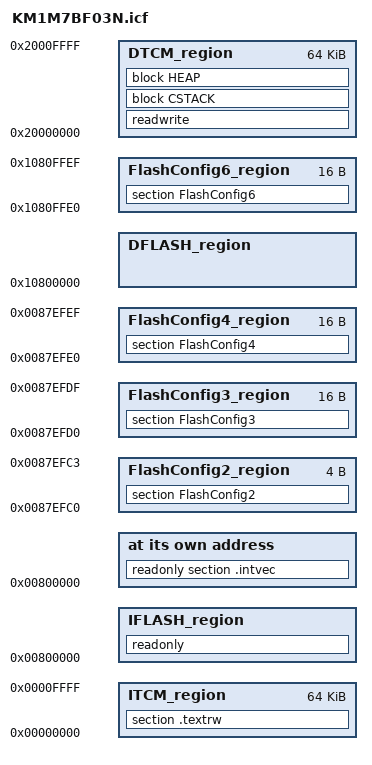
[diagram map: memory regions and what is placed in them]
/*###ICF### Section handled by ICF editor, don't touch! ****/
/*-Editor annotation file-*/
/* IcfEditorFile="$TOOLKIT_DIR$\config\ide\IcfEditor\cortex_v1_0.xml" */
/*-Specials-*/
define symbol __ICFEDIT_intvec_start__ = 0x00800000;
/*-Memory Regions-*/
define symbol __ICFEDIT_region_DTCM_start__      = 0x20000000;
define symbol __ICFEDIT_region_DTCM_end__        = 0x2000FFFF;
define symbol __ICFEDIT_region_DFLASH_start__    = 0x10800000;
define symbol __ICFEDIT_region_DFLASH_end__      = 0x1080FFFF;
define symbol __ICFEDIT_region_IFLASH_start__    = 0x00800000;
define symbol __ICFEDIT_region_IFLASH_end__      = 0x0087FFFF;
define symbol __ICFEDIT_region_ITCM_start__      = 0x00000000;
define symbol __ICFEDIT_region_ITCM_end__        = 0x0000FFFF;
/*-Sizes-*/
define symbol __ICFEDIT_size_cstack__ = 0x400;
define symbol __ICFEDIT_size_heap__   = 0x800;
/**** End of ICF editor section. ###ICF###*/

/**** Special settings for target device ****/

/*- Define symbols -*/
define symbol __FlashConfig1_start__ = 0x0087FFF8;
define symbol __FlashConfig1_end__   = 0x0087FFF8;
define symbol __FlashConfig2_start__ = 0x0087EFC0;
define symbol __FlashConfig2_end__   = 0x0087EFC3;
define symbol __FlashConfig3_start__ = 0x0087EFD0;
define symbol __FlashConfig3_end__   = 0x0087EFDF;
define symbol __FlashConfig4_start__ = 0x0087EFE0;
define symbol __FlashConfig4_end__   = 0x0087EFEF;
define symbol __FlashConfig6_start__ = 0x1080FFE0;
define symbol __FlashConfig6_end__   = 0x1080FFEF;

/* Define the memory space of 4G bytes named "mem" */
define memory mem with size = 4G;

/*- Define region in memory -*/
define region IFLASH_region    = mem:[from __ICFEDIT_region_IFLASH_start__ to __ICFEDIT_region_IFLASH_end__] - mem:[from __FlashConfig1_start__ to __FlashConfig1_end__] - mem:[from __FlashConfig2_start__ to __FlashConfig2_end__] - mem:[from __FlashConfig3_start__ to __FlashConfig3_end__] - mem:[from __FlashConfig4_start__ to __FlashConfig4_end__];
define region DFLASH_region    = mem:[from __ICFEDIT_region_DFLASH_start__ to __ICFEDIT_region_DFLASH_end__] - mem:[from __FlashConfig6_start__ to __FlashConfig6_end__];
define region ITCM_region      = mem:[from __ICFEDIT_region_ITCM_start__ to __ICFEDIT_region_ITCM_end__];
define region DTCM_region      = mem:[from __ICFEDIT_region_DTCM_start__ to __ICFEDIT_region_DTCM_end__];

define region FlashConfig1_region = mem:[from __FlashConfig1_start__ to __FlashConfig1_end__];
define region FlashConfig2_region = mem:[from __FlashConfig2_start__ to __FlashConfig2_end__];
define region FlashConfig3_region = mem:[from __FlashConfig3_start__ to __FlashConfig3_end__];
define region FlashConfig4_region = mem:[from __FlashConfig4_start__ to __FlashConfig4_end__];
define region FlashConfig6_region = mem:[from __FlashConfig6_start__ to __FlashConfig6_end__];

/*- Define block -*/
define block CSTACK    with alignment = 8, size = __ICFEDIT_size_cstack__   { };
define block HEAP      with alignment = 8, size = __ICFEDIT_size_heap__     { };

/*- Initialize type -*/
initialize by copy { readwrite };
do not initialize  { section .noinit };

/*- Set placement in memory or region -*/
place at address mem:__ICFEDIT_intvec_start__ { readonly section .intvec };

place in IFLASH_region    { readonly };
place in ITCM_region      { section .textrw };
place in DTCM_region      { readwrite, block CSTACK, block HEAP };

place in FlashConfig1_region { section FlashConfig1 };
place in FlashConfig2_region { section FlashConfig2 };
place in FlashConfig3_region { section FlashConfig3 };
place in FlashConfig4_region { section FlashConfig4 };
place in FlashConfig6_region { section FlashConfig6 };
